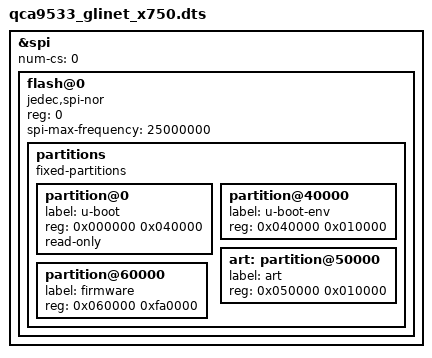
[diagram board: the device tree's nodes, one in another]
// SPDX-License-Identifier: GPL-2.0-or-later OR MIT
/dts-v1/;

#include <dt-bindings/gpio/gpio.h>
#include <dt-bindings/input/input.h>

#include "qca9533_glinet_x750.dtsi"

&spi {
	status = "okay";
	num-cs = <0>;

	flash@0 {
		compatible = "jedec,spi-nor";
		reg = <0>;
		spi-max-frequency = <25000000>;

		partitions {
			compatible = "fixed-partitions";
			#address-cells = <1>;
			#size-cells = <1>;

			partition@0 {
				label = "u-boot";
				reg = <0x000000 0x040000>;
				read-only;
			};

			partition@40000 {
				label = "u-boot-env";
				reg = <0x040000 0x010000>;
			};

                        art: partition@50000 {
                                label = "art";
                                reg = <0x050000 0x010000>;
                        };

			partition@60000 {
				label = "firmware";
				reg = <0x060000 0xfa0000>;
			};

		};
	};
};
